VERSION ""

NS_ :

BS_:

BU_: PDC ADV APA GW LCDAM AVM

BO_ 3221225472 VECTOR__INDEPENDENT_SIG_MSG: 0 Vector__XXX
 SG_ FogLightSt_FR : 0|1@1+ (1,0) [0|1] "" Vector__XXX
 SG_ FogLightSt_FL : 0|1@1+ (1,0) [0|1] "" Vector__XXX
 SG_ PDC_SpeechControlFeedback : 0|3@1+ (1,0) [0|0] "" Vector__XXX
 SG_ MinObjectRange : 0|4@1+ (1,0) [0|0] "" Vector__XXX
 SG_ RadarSysSt_Side : 0|1@1+ (1,0) [0|0] "" Vector__XXX

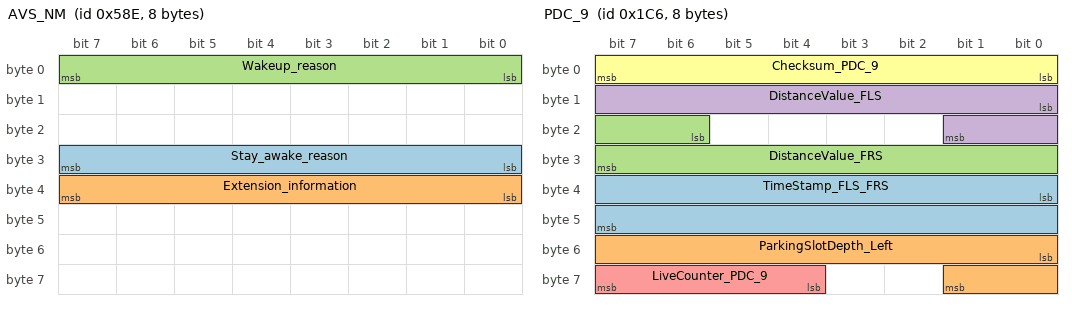
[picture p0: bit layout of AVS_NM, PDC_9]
BO_ 1422 AVS_NM: 8 AVM
 SG_ Stay_awake_reason : 24|8@1+ (1,0) [0|0] "" Vector__XXX
 SG_ Extension_information : 32|8@1+ (1,0) [0|0] "" Vector__XXX
 SG_ Wakeup_reason : 0|8@1+ (1,0) [0|0] "" Vector__XXX

BO_ 454 PDC_9: 8 APA
 SG_ TimeStamp_FLS_FRS : 32|16@1+ (1,0) [0|0] ""  AVM
 SG_ ParkingSlotDepth_Left : 48|10@1+ (1,0) [0|0] ""  AVM
 SG_ DistanceValue_FRS : 22|10@1+ (1,0) [0|0] ""  AVM
 SG_ DistanceValue_FLS : 8|10@1+ (1,0) [0|0] ""  AVM
 SG_ LiveCounter_PDC_9 : 60|4@1+ (1,0) [0|15] ""  AVM
 SG_ Checksum_PDC_9 : 0|8@1+ (1,0) [0|255] ""  AVM

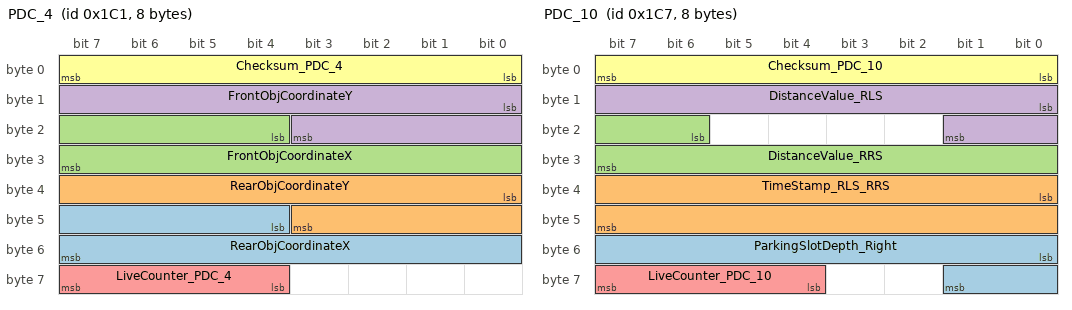
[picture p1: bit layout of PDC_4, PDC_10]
BO_ 449 PDC_4: 8 APA
 SG_ RearObjCoordinateX : 44|12@1+ (2,-4000) [-4000|4000] ""  AVM
 SG_ RearObjCoordinateY : 32|12@1+ (2,-4000) [-4000|4000] ""  AVM
 SG_ FrontObjCoordinateX : 20|12@1+ (2,-4000) [-4000|4000] ""  AVM
 SG_ FrontObjCoordinateY : 8|12@1+ (2,-4000) [-4000|4000] ""  AVM
 SG_ LiveCounter_PDC_4 : 60|4@1+ (1,0) [0|15] ""  AVM
 SG_ Checksum_PDC_4 : 0|8@1+ (1,0) [0|255] ""  AVM

BO_ 455 PDC_10: 8 APA
 SG_ ParkingSlotDepth_Right : 48|10@1+ (1,0) [0|0] ""  AVM
 SG_ TimeStamp_RLS_RRS : 32|16@1+ (1,0) [0|0] ""  AVM
 SG_ DistanceValue_RRS : 22|10@1+ (1,0) [0|0] ""  AVM
 SG_ DistanceValue_RLS : 8|10@1+ (1,0) [0|0] ""  AVM
 SG_ LiveCounter_PDC_10 : 60|4@1+ (1,0) [0|15] ""  AVM
 SG_ Checksum_PDC_10 : 0|8@1+ (1,0) [0|255] ""  AVM

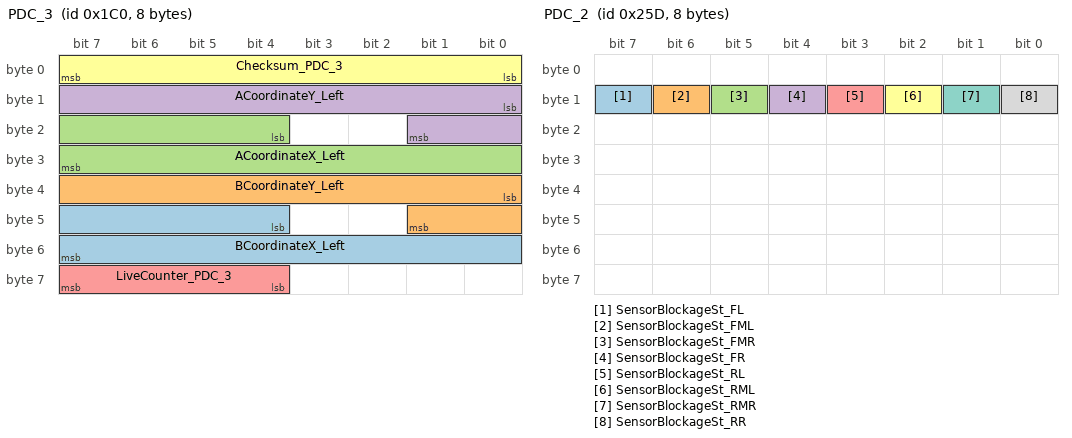
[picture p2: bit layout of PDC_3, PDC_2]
BO_ 448 PDC_3: 8 APA
 SG_ BCoordinateX_Left : 44|12@1+ (1,0) [0|0] ""  AVM
 SG_ BCoordinateY_Left : 32|10@1+ (1,0) [0|0] ""  AVM
 SG_ ACoordinateX_Left : 20|12@1+ (1,0) [0|0] ""  AVM
 SG_ ACoordinateY_Left : 8|10@1+ (1,0) [0|0] ""  AVM
 SG_ LiveCounter_PDC_3 : 60|4@1+ (1,0) [0|15] ""  AVM
 SG_ Checksum_PDC_3 : 0|8@1+ (1,0) [0|255] ""  AVM

BO_ 605 PDC_2: 8 PDC
 SG_ SensorBlockageSt_FL : 15|1@1+ (1,0) [0|0] ""  AVM
 SG_ SensorBlockageSt_FML : 14|1@1+ (1,0) [0|0] ""  AVM
 SG_ SensorBlockageSt_FMR : 13|1@1+ (1,0) [0|0] ""  AVM
 SG_ SensorBlockageSt_FR : 12|1@1+ (1,0) [0|0] ""  AVM
 SG_ SensorBlockageSt_RL : 11|1@1+ (1,0) [0|0] ""  AVM
 SG_ SensorBlockageSt_RML : 10|1@1+ (1,0) [0|0] ""  AVM
 SG_ SensorBlockageSt_RMR : 9|1@1+ (1,0) [0|0] ""  AVM
 SG_ SensorBlockageSt_RR : 8|1@1+ (1,0) [0|0] ""  AVM

BO_ 616 LCDA_1: 8 LCDAM
 SG_ WarningCmd_RCTA_Right : 20|2@1+ (1,0) [0|0] ""  AVM
 SG_ WarningCmd_RCTA_left : 16|2@1+ (1,0) [0|0] ""  AVM

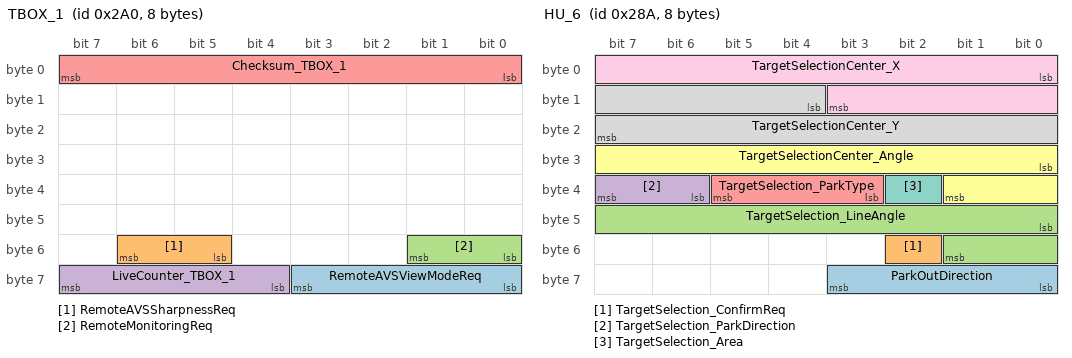
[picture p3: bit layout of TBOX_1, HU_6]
BO_ 672 TBOX_1: 8 GW
 SG_ RemoteAVSViewModeReq : 56|4@1+ (1,0) [0|0] ""  AVM
 SG_ RemoteAVSSharpnessReq : 53|2@1+ (1,0) [0|0] ""  AVM
 SG_ RemoteMonitoringReq : 48|2@1+ (1,0) [0|0] ""  AVM
 SG_ LiveCounter_TBOX_1 : 60|4@1+ (1,0) [0|15] ""  AVM
 SG_ Checksum_TBOX_1 : 0|8@1+ (1,0) [0|255] ""  AVM

BO_ 591 RRDCU_1: 8 GW
 SG_ DoorSt_RR : 2|1@1+ (1,0) [0|0] ""  AVM

BO_ 590 RLDCU_1: 8 GW
 SG_ DoorSt_RL : 2|1@1+ (1,0) [0|0] ""  AVM

BO_ 420 MCP_1: 8 GW
 SG_ MCP_AVSandFRadarSwitch : 25|1@1- (1,0) [0|0] ""  AVM

BO_ 650 HU_6: 8 GW
 SG_ ParkOutDirection : 56|4@1+ (1,0) [0|0] ""  AVM
 SG_ TargetSelection_ConfirmReq : 50|1@1+ (1,0) [0|0] ""  AVM
 SG_ TargetSelection_LineAngle : 40|10@1+ (1,0) [0|0] ""  AVM
 SG_ TargetSelection_ParkDirection : 38|2@1+ (1,0) [0|0] ""  AVM
 SG_ TargetSelection_ParkType : 35|3@1+ (1,0) [0|0] ""  AVM
 SG_ TargetSelectionCenter_Angle : 24|10@1+ (1,0) [0|360] ""  AVM
 SG_ TargetSelection_Area : 34|1@1+ (1,0) [0|0] ""  AVM
 SG_ TargetSelectionCenter_Y : 12|12@1+ (1,0) [0|719] ""  AVM
 SG_ TargetSelectionCenter_X : 0|12@1+ (1,0) [0|2607] ""  AVM

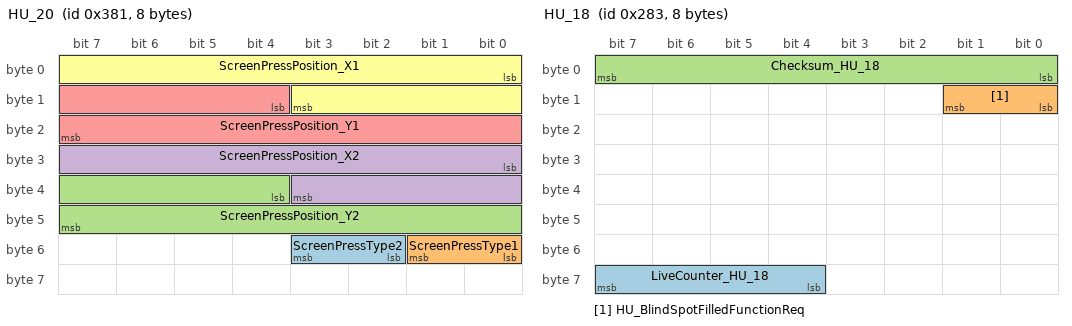
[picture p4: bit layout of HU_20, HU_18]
BO_ 897 HU_20: 8 GW
 SG_ ScreenPressType2 : 50|2@1+ (1,0) [0|0] ""  AVM
 SG_ ScreenPressType1 : 48|2@1+ (1,0) [0|0] ""  AVM
 SG_ ScreenPressPosition_Y2 : 36|12@1+ (1,0) [0|720] ""  AVM
 SG_ ScreenPressPosition_X2 : 24|12@1+ (1,0) [0|2607] ""  AVM
 SG_ ScreenPressPosition_Y1 : 12|12@1+ (1,0) [0|720] ""  AVM
 SG_ ScreenPressPosition_X1 : 0|12@1+ (1,0) [0|2607] ""  AVM

BO_ 643 HU_18: 8 GW
 SG_ LiveCounter_HU_18 : 60|4@1- (1,0) [0|0] ""  AVM
 SG_ HU_BlindSpotFilledFunctionReq : 8|2@1+ (1,0) [0|0] ""  AVM
 SG_ Checksum_HU_18 : 0|8@1+ (1,0) [0|0] ""  AVM

BO_ 657 HU_14: 8 GW
 SG_ DisplayTheme : 24|3@1+ (1,0) [0|0] ""  AVM

BO_ 688 GW_Config: 8 GW
 SG_ GW_OTAMode : 16|3@1+ (1,0) [0|0] ""  AVM
 SG_ GW_RemoteVehicleMode : 12|1@1+ (1,0) [0|0] ""  AVM

BO_ 534 DMS_2: 8 GW
 SG_ DMS_VehicleModeInfo : 8|4@1+ (1,0) [0|0] ""  AVM

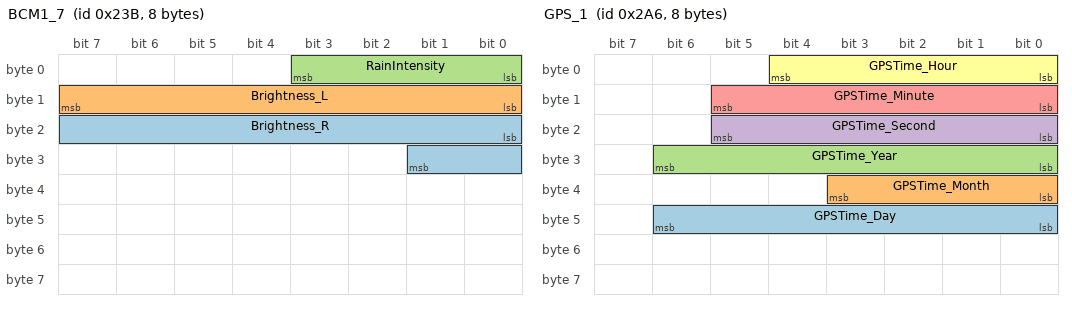
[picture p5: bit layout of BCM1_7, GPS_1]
BO_ 571 BCM1_7: 8 GW
 SG_ Brightness_R : 16|10@1+ (6,0) [0|0] ""  AVM
 SG_ Brightness_L : 8|8@1+ (400,0) [0|0] ""  AVM
 SG_ RainIntensity : 0|4@1+ (10,0) [0|0] ""  AVM

BO_ 564 BCM1_3: 8 GW
 SG_ EngineHoodSt : 12|1@1+ (1,0) [0|0] ""  AVM

BO_ 604 PDC_1: 8 PDC
 SG_ SwitchScreenRequest_PDC : 54|2@1+ (1,0) [0|0] ""  AVM
 SG_ PDCAutoOnFunctionInd : 53|1@1+ (1,0) [0|0] ""  AVM
 SG_ RadarSysSt_RearSide : 12|1@1- (1,0) [0|0] ""  AVM
 SG_ RadarSysSt_FrontSide : 11|1@1- (1,0) [0|0] ""  AVM
 SG_ SensorErrorSt_FL : 47|1@1+ (1,0) [0|0] ""  AVM
 SG_ ObjectRange_FL : 44|3@1+ (1,0) [0|0] ""  AVM
 SG_ SensorErrorSt_FML : 43|1@1+ (1,0) [0|0] ""  AVM
 SG_ ObjectRange_FML : 40|3@1+ (1,0) [0|0] ""  AVM
 SG_ SensorErrorSt_FMR : 39|1@1+ (1,0) [0|0] ""  AVM
 SG_ ObjectRange_FMR : 36|3@1+ (1,0) [0|0] ""  AVM
 SG_ SensorErrorSt_FR : 35|1@1+ (1,0) [0|0] ""  AVM
 SG_ ObjectRange_FR : 32|3@1+ (1,0) [0|0] ""  AVM
 SG_ SensorErrorSt_RL : 31|1@1+ (1,0) [0|0] ""  AVM
 SG_ ObjectRange_RL : 28|3@1+ (1,0) [0|7] ""  AVM
 SG_ SensorErrorSt_RML : 27|1@1+ (1,0) [0|0] ""  AVM
 SG_ ObjectRange_RML : 24|3@1+ (1,0) [0|0] ""  AVM
 SG_ SensorErrorSt_RMR : 23|1@1+ (1,0) [0|1] ""  AVM
 SG_ BuzeerCmd_PDC : 5|3@1+ (1,0) [0|0] ""  AVM
 SG_ ObjectRange_RMR : 20|3@1+ (1,0) [0|0] ""  AVM
 SG_ SensorErrorSt_RR : 19|1@1+ (1,0) [0|0] ""  AVM
 SG_ ObjectRange_RR : 16|3@1+ (1,0) [0|0] ""  AVM
 SG_ RadarSysSt_Rear : 3|1@1+ (1,0) [0|0] ""  AVM
 SG_ RadarSysSt_Front : 2|1@1+ (1,0) [0|0] ""  AVM
 SG_ ErrorSt_PDC : 1|1@1+ (1,0) [0|0] ""  AVM
 SG_ SysSt_PDC : 0|1@1+ (1,0) [0|0] ""  AVM

BO_ 546 ATC_2: 8 GW
 SG_ AmbientTemp : 24|8@1- (0.5,-40) [-40|86.5] ""  AVM

BO_ 678 GPS_1: 8 GW
 SG_ GPSTime_Day : 40|7@1+ (1,0) [0|30] ""  AVM
 SG_ GPSTime_Month : 32|4@1+ (1,0) [0|11] ""  AVM
 SG_ GPSTime_Year : 24|7@1+ (1,0) [0|125] ""  AVM
 SG_ GPSTime_Second : 16|6@1+ (1,0) [0|59] ""  AVM
 SG_ GPSTime_Minute : 8|6@1+ (1,0) [0|59] ""  AVM
 SG_ GPSTime_Hour : 0|5@1+ (1,0) [0|23] ""  AVM

BO_ 588 PDCU_1: 8 GW
 SG_ MirrorFoldSt_FR : 34|2@1+ (1,0) [0|0] ""  AVM
 SG_ DoorSt_FR : 2|1@1+ (1,0) [0|1] ""  AVM

BO_ 578 PLG_1: 8 GW
 SG_ LuggageDoorSt : 0|1@1+ (1,0) [0|0] ""  AVM

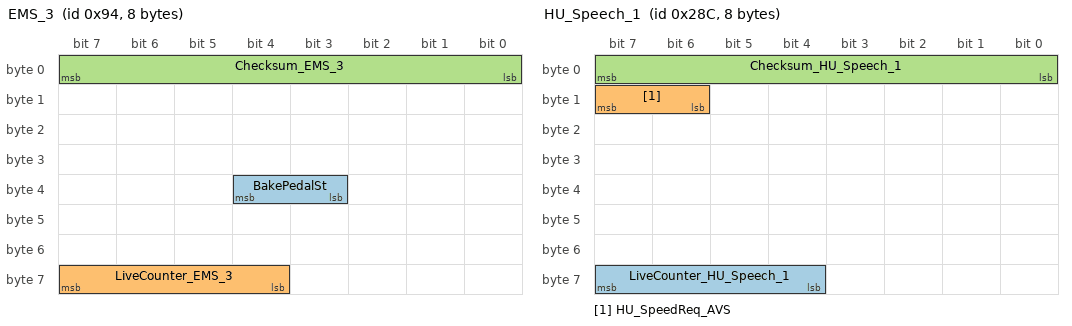
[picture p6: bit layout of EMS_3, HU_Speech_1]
BO_ 148 EMS_3: 8 GW
 SG_ BakePedalSt : 35|2@1+ (1,0) [0|0] ""  AVM
 SG_ LiveCounter_EMS_3 : 60|4@1+ (1,0) [0|15] ""  AVM
 SG_ Checksum_EMS_3 : 0|8@1+ (1,0) [0|255] ""  AVM

BO_ 652 HU_Speech_1: 8 GW
 SG_ LiveCounter_HU_Speech_1 : 60|4@1+ (1,0) [0|15] ""  PDC,AVM
 SG_ HU_SpeedReq_AVS : 14|2@1+ (1,0) [0|0] ""  PDC,AVM
 SG_ Checksum_HU_Speech_1 : 0|8@1+ (1,0) [0|255] ""  PDC,AVM

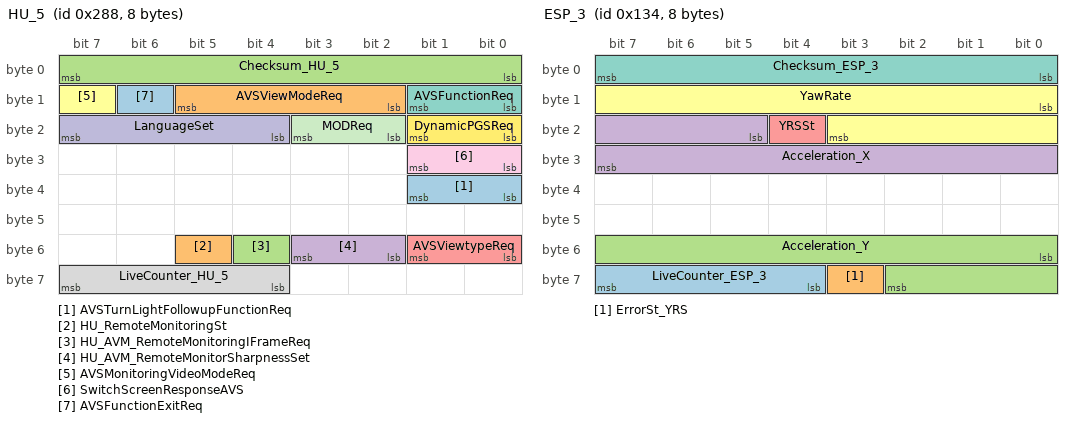
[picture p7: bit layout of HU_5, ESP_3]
BO_ 648 HU_5: 8 GW
 SG_ AVSTurnLightFollowupFunctionReq : 32|2@1+ (1,0) [0|0] ""  AVM
 SG_ HU_RemoteMonitoringSt : 53|1@1+ (1,0) [0|0] ""  AVM
 SG_ HU_AVM_RemoteMonitoringIFrameReq : 52|1@1+ (1,0) [0|0] ""  AVM
 SG_ HU_AVM_RemoteMonitorSharpnessSet : 50|2@1+ (1,0) [0|0] ""  AVM
 SG_ AVSViewtypeReq : 48|2@1+ (1,0) [0|0] ""  AVM
 SG_ AVSMonitoringVideoModeReq : 15|1@1+ (1,0) [0|0] ""  AVM
 SG_ AVSFunctionReq : 8|2@1+ (1,0) [0|0] ""  AVM
 SG_ LiveCounter_HU_5 : 60|4@1+ (1,0) [0|15] ""  AVM
 SG_ SwitchScreenResponseAVS : 24|2@1+ (1,0) [0|0] ""  AVM
 SG_ LanguageSet : 20|4@1+ (1,0) [0|0] ""  AVM
 SG_ MODReq : 18|2@1+ (1,0) [0|0] ""  AVM
 SG_ DynamicPGSReq : 16|2@1+ (1,0) [0|0] ""  AVM
 SG_ AVSFunctionExitReq : 14|1@1+ (1,0) [0|0] ""  AVM
 SG_ AVSViewModeReq : 10|4@1+ (1,0) [0|0] ""  AVM
 SG_ Checksum_HU_5 : 0|8@1+ (1,0) [0|255] ""  AVM

BO_ 308 ESP_3: 8 GW
 SG_ LiveCounter_ESP_3 : 60|4@1+ (1,0) [0|0] ""  AVM
 SG_ ErrorSt_YRS : 59|1@1+ (1,0) [0|0] ""  AVM
 SG_ Acceleration_Y : 48|11@1- (0.027127,-21.593) [-21.593|21.593184] ""  AVM
 SG_ Acceleration_X : 21|11@1+ (0.027127,-21.593) [-21.593|21.593184] ""  AVM
 SG_ YRSSt : 20|1@1+ (1,0) [0|15] ""  AVM
 SG_ YawRate : 8|12@1- (0.05,-100) [-100|100] ""  AVM
 SG_ Checksum_ESP_3 : 0|8@1+ (1,0) [0|255] ""  AVM

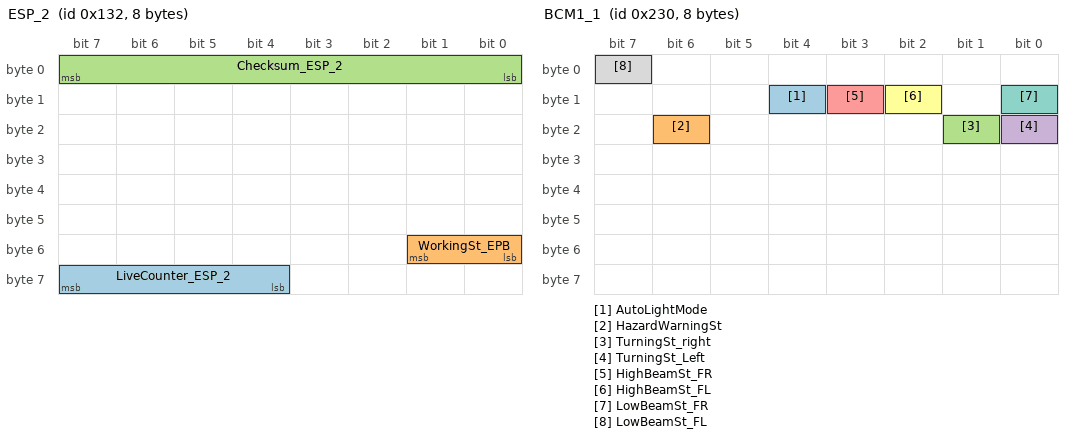
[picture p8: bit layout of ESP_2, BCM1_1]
BO_ 306 ESP_2: 8 GW
 SG_ LiveCounter_ESP_2 : 60|4@1+ (1,0) [0|15] ""  AVM
 SG_ WorkingSt_EPB : 48|2@1+ (1,0) [0|0] ""  AVM
 SG_ Checksum_ESP_2 : 0|8@1+ (1,0) [0|255] ""  AVM

BO_ 586 DDCU_1: 8 GW
 SG_ DoorSt_FL : 2|1@1+ (1,0) [0|0] ""  AVM
 SG_ MirrorFoldSt_FL : 34|2@1+ (1,0) [0|0] ""  AVM

BO_ 560 BCM1_1: 8 GW
 SG_ AutoLightMode : 12|1@1+ (1,0) [0|0] ""  AVM
 SG_ HazardWarningSt : 22|1@1+ (1,0) [0|15] ""  AVM
 SG_ TurningSt_right : 17|1@1+ (1,0) [0|3] ""  AVM
 SG_ TurningSt_Left : 16|1@1+ (1,0) [0|1] ""  AVM
 SG_ HighBeamSt_FR : 11|1@1+ (1,0) [0|1] ""  AVM
 SG_ HighBeamSt_FL : 10|1@1+ (1,0) [0|1] ""  AVM
 SG_ LowBeamSt_FR : 8|1@1+ (1,0) [0|1] ""  AVM
 SG_ LowBeamSt_FL : 7|1@1+ (1,0) [0|1] ""  AVM

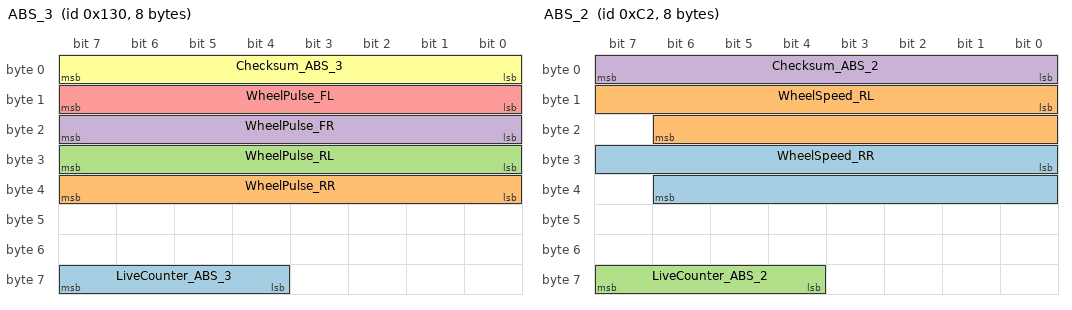
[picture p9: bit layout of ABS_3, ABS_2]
BO_ 304 ABS_3: 8 GW
 SG_ LiveCounter_ABS_3 : 60|4@1+ (1,0) [0|15] ""  AVM
 SG_ WheelPulse_RR : 32|8@1+ (1,0) [0|253] ""  AVM
 SG_ WheelPulse_RL : 24|8@1+ (1,0) [0|253] ""  AVM
 SG_ WheelPulse_FR : 16|8@1+ (1,0) [0|253] ""  AVM
 SG_ WheelPulse_FL : 8|8@1+ (1,0) [0|253] ""  AVM
 SG_ Checksum_ABS_3 : 0|8@1+ (1,0) [0|255] ""  AVM

BO_ 194 ABS_2: 8 GW
 SG_ WheelSpeed_RR : 24|15@1+ (0.01,0) [0|32765] ""  AVM
 SG_ WheelSpeed_RL : 8|15@1+ (0.01,0) [0|32765] ""  AVM
 SG_ LiveCounter_ABS_2 : 60|4@1+ (1,0) [0|15] ""  AVM
 SG_ Checksum_ABS_2 : 0|8@1+ (1,0) [0|255] ""  AVM

BO_ 2015 Diag_Fun_Req: 8 GW
 SG_ Diag_Fun_Req : 0|64@1+ (1,0) [0|0] ""  AVM,GW

BO_ 1838 AVS_Phy_Resp: 8 AVM
 SG_ AVS_Phy_Resp : 0|64@1+ (1,0) [0|0] ""  GW

BO_ 1830 AVS_Phy_Req: 8 GW
 SG_ AVS_Phy_Req : 0|64@1+ (1,0) [0|0] ""  AVM

BO_ 656 IC_1: 8 GW
 SG_ HandParkingBrakeSt : 49|2@1+ (1,0) [0|0] ""  AVM,PDC
 SG_ OdometerValue : 24|25@1+ (0.1,0) [0|33554430] ""  AVM

BO_ 562 BCM1_2: 8 GW
 SG_ PowerMode : 4|4@1- (1,0) [0|0] ""  AVM

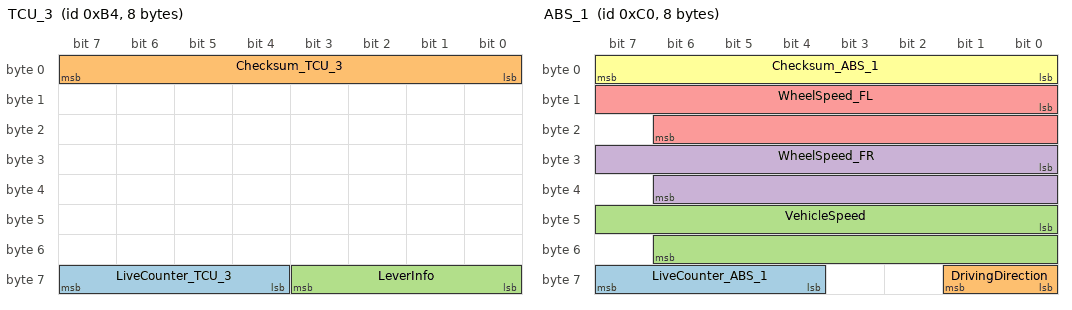
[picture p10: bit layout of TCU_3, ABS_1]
BO_ 180 TCU_3: 8 GW
 SG_ LiveCounter_TCU_3 : 60|4@1+ (1,0) [0|15] ""  PDC
 SG_ Checksum_TCU_3 : 0|8@1+ (1,0) [0|255] ""  PDC
 SG_ LeverInfo : 56|4@1+ (1,0) [0|15] ""  AVM

BO_ 192 ABS_1: 8 GW
 SG_ LiveCounter_ABS_1 : 60|4@1+ (1,0) [0|15] ""  AVM
 SG_ DrivingDirection : 56|2@1+ (1,0) [0|3] ""  AVM
 SG_ VehicleSpeed : 40|15@1+ (0.01,0) [0|32765] ""  AVM
 SG_ WheelSpeed_FR : 24|15@1+ (0.01,0) [0|32765] ""  AVM
 SG_ WheelSpeed_FL : 8|15@1+ (0.01,0) [0|32765] ""  AVM
 SG_ Checksum_ABS_1 : 0|8@1+ (1,0) [0|255] ""  AVM

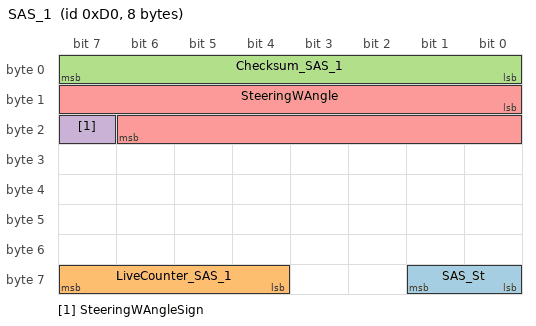
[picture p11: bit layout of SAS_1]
BO_ 208 SAS_1: 8 GW
 SG_ SAS_St : 56|2@1+ (1,0) [0|0] ""  AVM
 SG_ LiveCounter_SAS_1 : 60|4@1+ (1,0) [0|15] ""  AVM
 SG_ Checksum_SAS_1 : 0|8@1+ (1,0) [0|255] ""  AVM
 SG_ SteeringWAngleSign : 23|1@1+ (1,0) [0|1] ""  AVM
 SG_ SteeringWAngle : 8|15@1+ (0.04375,0) [0|32766] ""  AVM

BO_ 600 AVS_1: 8 AVM
 SG_ AVSTurnLightFollowupFunctionSt : 20|1@1+ (1,0) [0|0] ""  GW
 SG_ AVS_RemoteViewModeFeedback : 59|5@1+ (1,0) [0|0] ""  GW
 SG_ RemoteMonitoringModeSt_AVS : 56|1@1+ (1,0) [0|0] ""  GW
 SG_ RemoteMonitoringSt_AVS : 55|1@1+ (1,0) [0|0] ""  GW
 SG_ RemoteMonitoringSharpnessSt_AVS : 54|1@1+ (1,0) [0|0] ""  GW
 SG_ AVS_RemoteSharpnessFeedback : 51|3@1+ (1,0) [0|0] ""  GW
 SG_ AVS_RemoteMonitoringFeedback : 48|3@1+ (1,0) [0|0] ""  GW
 SG_ AVS_PDWarning_Rear : 47|1@1+ (1,0) [0|0] ""  GW
 SG_ AVS_PDWarning_Front : 46|1@1+ (1,0) [0|0] ""  GW
 SG_ AVS_CalibrationSt : 44|2@1+ (1,0) [0|0] ""  ADV
 SG_ AVS_AbnormalTip : 41|3@1+ (1,0) [0|0] ""  GW
 SG_ AVSCameraBlockageSt_Right : 40|1@1+ (1,0) [0|0] ""  GW
 SG_ AVSCameraBlockageSt_Left : 39|1@1+ (1,0) [0|0] ""  GW
 SG_ AVSCameraBlockageSt_Rear : 38|1@1+ (1,0) [0|0] ""  GW
 SG_ AVSCameraBlockageSt_Front : 37|1@1+ (1,0) [0|0] ""  GW
 SG_ FoundSlotBuzzerTip : 27|1@1+ (1,0) [0|0] ""  GW
 SG_ BlindSpotFilledFunctionInd : 26|1@1+ (1,0) [0|0] ""  GW,ADV
 SG_ MODWarning_Rear : 19|1@1+ (1,0) [0|0] ""  ADV,GW
 SG_ MODWarning_Front : 18|1@1+ (1,0) [0|0] ""  ADV,GW
 SG_ MODSt_AVS : 17|1@1+ (1,0) [0|0] ""  GW
 SG_ AVSViewtype : 6|2@1+ (1,0) [0|0] ""  GW
 SG_ AVS_SpeechControlFeedback : 32|5@1+ (1,0) [0|0] "" Vector__XXX
 SG_ SwitchScreenRequest_AVS : 24|2@1+ (1,0) [0|0] ""  GW
 SG_ DybanicPGSSt_AVS : 16|1@1+ (1,0) [0|0] ""  GW
 SG_ AVSCameraErrorSt_Right : 11|1@1+ (1,0) [0|0] ""  GW
 SG_ AVSCameraErrorSt_Rear : 9|1@1+ (1,0) [0|0] ""  GW
 SG_ AVSCameraErrorSt_Left : 10|1@1+ (1,0) [0|0] ""  GW
 SG_ LanguageTypeSt_AVS : 12|4@1+ (1,0) [0|7] ""  GW
 SG_ AVSCameraErrorSt_Front : 8|1@1+ (1,0) [0|0] ""  GW
 SG_ AVSSt : 0|1@1+ (1,0) [0|0] ""  PDC,GW
 SG_ AVSViewMode : 2|4@1+ (1,0) [0|7] ""  GW
 SG_ AVSErrorSt : 1|1@1+ (1,0) [0|1] ""  ADV,GW

BO_TX_BU_ 605 : APA,PDC;
BO_TX_BU_ 604 : APA,PDC;

CM_ "

";
CM_ BO_ 3221225472 "This is a message for not used signals, created by Vector CANdb++ DBC OLE DB Provider.";
BA_DEF_ BO_  "GenSigTimeoutTime_DUT" INT 0 100000;
BA_DEF_ BU_  "NmStationAddress" HEX 0 255;
BA_DEF_ SG_  "GenSigInactiveValue" INT 0 100000;
BA_DEF_ SG_  "GenSigSendType" ENUM  "Cyclic","OnWrite","OnWriteWithRepetition","OnChange","OnChangeWithRepetition","IfActive","IfActiveWithRepetition","NoSigSendType","OnChangeAndIfActive","OnChangeAndIfActiveWithRepetition";
BA_DEF_ SG_  "GenSigStartValue" INT 0 65535;
BA_DEF_ BO_  "GenMsgCycleTime" INT 0 65535;
BA_DEF_ BO_  "GenMsgSendType" ENUM  "Cyclic ","NotUsed ","NotUsed ","NotUsed ","NotUsed ","NotUsed ","NotUsed ","IfActive ","NoMsgSendType";
BA_DEF_ BO_  "DiagRequest" ENUM  "No","Yes";
BA_DEF_ BO_  "DiagResponse" ENUM  "No","Yes";
BA_DEF_ BO_  "DiagState" ENUM  "No","Yes";
BA_DEF_ BO_  "GenMsgILSupport" ENUM  "No","Yes";
BA_DEF_ BU_  "ILUsed" ENUM  "No","Yes";
BA_DEF_ BU_  "NmAsrNode" ENUM  "No","Yes";
BA_DEF_  "Baudrate" INT 0 0;
BA_DEF_  "NmType" STRING ;
BA_DEF_  "Manufacturer" STRING ;
BA_DEF_  "ILTxTimeout" INT 0 65535;
BA_DEF_  "DBName" STRING ;
BA_DEF_  "BusType" STRING ;
BA_DEF_ BO_  "NmAsrMessage" ENUM  "No","Yes";
BA_DEF_ BU_  "NmAsrCanMsgReducedTime" INT 0 0;
BA_DEF_  "NmAsrRepeatMessageTime" INT 0 0;
BA_DEF_  "NmAsrWaitBusSleepTime" INT 0 0;
BA_DEF_  "NmAsrTimeoutTime" INT 0 0;
BA_DEF_  "NmAsrCanMsgCycleTime" INT 0 0;
BA_DEF_  "NmAsrMessageCount" INT 0 256;
BA_DEF_ BU_  "NmAsrNodeIdentifier" HEX 0 255;
BA_DEF_  "NmAsrBaseAddress" HEX 0 0;
BA_DEF_ SG_  "GenSigTimeoutTime" INT 0 65535;
BA_DEF_DEF_  "GenSigTimeoutTime_DUT" 0;
BA_DEF_DEF_  "NmStationAddress" 0;
BA_DEF_DEF_  "GenSigInactiveValue" 0;
BA_DEF_DEF_  "GenSigSendType" "NoSigSendType";
BA_DEF_DEF_  "GenSigStartValue" 0;
BA_DEF_DEF_  "GenMsgCycleTime" 0;
BA_DEF_DEF_  "GenMsgSendType" "NoMsgSendType";
BA_DEF_DEF_  "DiagRequest" "No";
BA_DEF_DEF_  "DiagResponse" "No";
BA_DEF_DEF_  "DiagState" "No";
BA_DEF_DEF_  "GenMsgILSupport" "Yes";
BA_DEF_DEF_  "ILUsed" "Yes";
BA_DEF_DEF_  "NmAsrNode" "No";
BA_DEF_DEF_  "Baudrate" 500000;
BA_DEF_DEF_  "NmType" "NmPwrTrainChery";
BA_DEF_DEF_  "Manufacturer" "Chery";
BA_DEF_DEF_  "ILTxTimeout" 40;
BA_DEF_DEF_  "DBName" "";
BA_DEF_DEF_  "BusType" "CAN";
BA_DEF_DEF_  "NmAsrMessage" "No";
BA_DEF_DEF_  "NmAsrCanMsgReducedTime" 0;
BA_DEF_DEF_  "NmAsrRepeatMessageTime" 3200;
BA_DEF_DEF_  "NmAsrWaitBusSleepTime" 1500;
BA_DEF_DEF_  "NmAsrTimeoutTime" 2000;
BA_DEF_DEF_  "NmAsrCanMsgCycleTime" 640;
BA_DEF_DEF_  "NmAsrMessageCount" 64;
BA_DEF_DEF_  "NmAsrNodeIdentifier" 0;
BA_DEF_DEF_  "NmAsrBaseAddress" 0;
BA_DEF_DEF_  "GenSigTimeoutTime" 0;
BA_ "NmAsrTimeoutTime" 1000;
BA_ "NmAsrMessageCount" 128;
BA_ "NmAsrCanMsgCycleTime" 100;
BA_ "NmAsrWaitBusSleepTime" 5000;
BA_ "NmAsrRepeatMessageTime" 500;
BA_ "Manufacturer" "Vector";
BA_ "NmType" "NmAsr";
BA_ "ILTxTimeout" 0;
BA_ "NmAsrBaseAddress" 1408;
BA_ "DBName" "AB02_FAW_C095";
BA_ "NmStationAddress" BU_ AVM 14;
BA_ "NmAsrNode" BU_ AVM 1;
BA_ "NmAsrCanMsgReducedTime" BU_ AVM 575;
BA_ "NmAsrNodeIdentifier" BU_ AVM 14;
BA_ "NmAsrMessage" BO_ 1422 1;
BA_ "GenMsgILSupport" BO_ 1422 0;
BA_ "GenMsgSendType" BO_ 1422 0;
BA_ "GenMsgCycleTime" BO_ 1422 100;
BA_ "GenMsgSendType" BO_ 454 0;
BA_ "GenMsgCycleTime" BO_ 454 50;
BA_ "GenMsgSendType" BO_ 449 0;
BA_ "GenMsgCycleTime" BO_ 449 50;
BA_ "GenMsgSendType" BO_ 455 0;
BA_ "GenMsgCycleTime" BO_ 455 50;
BA_ "GenMsgSendType" BO_ 448 0;
BA_ "GenMsgCycleTime" BO_ 448 50;
BA_ "GenMsgSendType" BO_ 605 0;
BA_ "GenMsgCycleTime" BO_ 605 100;
BA_ "GenMsgSendType" BO_ 616 0;
BA_ "GenMsgCycleTime" BO_ 616 100;
BA_ "GenMsgSendType" BO_ 672 0;
BA_ "GenMsgCycleTime" BO_ 672 100;
BA_ "GenMsgSendType" BO_ 591 0;
BA_ "GenMsgCycleTime" BO_ 591 100;
BA_ "GenMsgSendType" BO_ 590 0;
BA_ "GenMsgCycleTime" BO_ 590 100;
BA_ "GenMsgSendType" BO_ 420 0;
BA_ "GenMsgCycleTime" BO_ 420 50;
BA_ "GenMsgSendType" BO_ 650 0;
BA_ "GenMsgCycleTime" BO_ 650 100;
BA_ "GenMsgSendType" BO_ 897 0;
BA_ "GenMsgCycleTime" BO_ 897 100;
BA_ "GenMsgSendType" BO_ 643 0;
BA_ "GenMsgCycleTime" BO_ 643 100;
BA_ "GenMsgSendType" BO_ 657 0;
BA_ "GenMsgCycleTime" BO_ 657 100;
BA_ "GenMsgSendType" BO_ 688 0;
BA_ "GenMsgCycleTime" BO_ 688 100;
BA_ "GenMsgSendType" BO_ 534 0;
BA_ "GenMsgCycleTime" BO_ 534 100;
BA_ "GenSigTimeoutTime_DUT" BO_ 534 500;
BA_ "GenMsgSendType" BO_ 571 0;
BA_ "GenMsgCycleTime" BO_ 571 100;
BA_ "GenSigTimeoutTime_DUT" BO_ 571 500;
BA_ "GenMsgSendType" BO_ 564 0;
BA_ "GenMsgCycleTime" BO_ 564 100;
BA_ "GenSigTimeoutTime_DUT" BO_ 564 500;
BA_ "GenMsgCycleTime" BO_ 604 100;
BA_ "GenMsgSendType" BO_ 604 0;
BA_ "GenMsgCycleTime" BO_ 546 100;
BA_ "GenMsgSendType" BO_ 546 0;
BA_ "GenMsgSendType" BO_ 678 0;
BA_ "GenMsgCycleTime" BO_ 678 100;
BA_ "GenMsgSendType" BO_ 588 0;
BA_ "GenMsgCycleTime" BO_ 588 100;
BA_ "GenMsgSendType" BO_ 578 0;
BA_ "GenMsgCycleTime" BO_ 578 100;
BA_ "GenMsgSendType" BO_ 148 0;
BA_ "GenMsgCycleTime" BO_ 148 10;
BA_ "GenMsgSendType" BO_ 652 0;
BA_ "GenMsgCycleTime" BO_ 652 100;
BA_ "GenMsgCycleTime" BO_ 648 100;
BA_ "GenMsgSendType" BO_ 648 0;
BA_ "GenMsgSendType" BO_ 308 0;
BA_ "GenMsgCycleTime" BO_ 308 20;
BA_ "GenMsgCycleTime" BO_ 306 20;
BA_ "GenMsgSendType" BO_ 306 0;
BA_ "GenMsgCycleTime" BO_ 586 100;
BA_ "GenMsgSendType" BO_ 586 0;
BA_ "GenMsgCycleTime" BO_ 560 100;
BA_ "GenMsgSendType" BO_ 560 0;
BA_ "GenMsgCycleTime" BO_ 304 20;
BA_ "GenMsgSendType" BO_ 304 0;
BA_ "GenMsgSendType" BO_ 194 0;
BA_ "GenMsgCycleTime" BO_ 194 10;
BA_ "DiagState" BO_ 2015 1;
BA_ "DiagResponse" BO_ 1838 1;
BA_ "DiagRequest" BO_ 1830 1;
BA_ "GenMsgSendType" BO_ 1830 0;
BA_ "GenMsgSendType" BO_ 656 0;
BA_ "GenMsgCycleTime" BO_ 656 100;
BA_ "GenSigTimeoutTime_DUT" BO_ 562 500;
BA_ "GenMsgCycleTime" BO_ 562 100;
BA_ "GenMsgSendType" BO_ 562 0;
BA_ "GenMsgCycleTime" BO_ 180 10;
BA_ "GenMsgSendType" BO_ 180 0;
BA_ "GenMsgCycleTime" BO_ 192 10;
BA_ "GenMsgSendType" BO_ 192 0;
BA_ "GenMsgCycleTime" BO_ 208 10;
BA_ "GenMsgSendType" BO_ 208 0;
BA_ "GenMsgCycleTime" BO_ 600 100;
BA_ "GenMsgSendType" BO_ 600 0;
BA_ "GenSigSendType" SG_ 3221225472 FogLightSt_FR 0;
BA_ "GenSigSendType" SG_ 3221225472 FogLightSt_FL 0;
BA_ "GenSigSendType" SG_ 3221225472 PDC_SpeechControlFeedback 1;
BA_ "GenSigSendType" SG_ 3221225472 MinObjectRange 1;
BA_ "GenSigSendType" SG_ 3221225472 RadarSysSt_Side 1;
BA_ "GenSigSendType" SG_ 1422 Stay_awake_reason 0;
BA_ "GenSigSendType" SG_ 1422 Extension_information 0;
BA_ "GenSigSendType" SG_ 1422 Wakeup_reason 0;
BA_ "GenSigSendType" SG_ 454 TimeStamp_FLS_FRS 0;
BA_ "GenSigSendType" SG_ 454 ParkingSlotDepth_Left 0;
BA_ "GenSigSendType" SG_ 454 DistanceValue_FRS 0;
BA_ "GenSigSendType" SG_ 454 DistanceValue_FLS 0;
BA_ "GenSigSendType" SG_ 454 LiveCounter_PDC_9 0;
BA_ "GenSigSendType" SG_ 454 Checksum_PDC_9 0;
BA_ "GenSigSendType" SG_ 449 RearObjCoordinateX 0;
BA_ "GenSigStartValue" SG_ 449 RearObjCoordinateX 2000;
BA_ "GenSigSendType" SG_ 449 RearObjCoordinateY 0;
BA_ "GenSigStartValue" SG_ 449 RearObjCoordinateY 2000;
BA_ "GenSigStartValue" SG_ 449 FrontObjCoordinateX 2000;
BA_ "GenSigSendType" SG_ 449 FrontObjCoordinateX 0;
BA_ "GenSigStartValue" SG_ 449 FrontObjCoordinateY 2000;
BA_ "GenSigSendType" SG_ 449 FrontObjCoordinateY 0;
BA_ "GenSigSendType" SG_ 449 LiveCounter_PDC_4 0;
BA_ "GenSigSendType" SG_ 449 Checksum_PDC_4 0;
BA_ "GenSigSendType" SG_ 455 ParkingSlotDepth_Right 0;
BA_ "GenSigSendType" SG_ 455 TimeStamp_RLS_RRS 0;
BA_ "GenSigSendType" SG_ 455 DistanceValue_RRS 0;
BA_ "GenSigSendType" SG_ 455 DistanceValue_RLS 0;
BA_ "GenSigSendType" SG_ 455 LiveCounter_PDC_10 0;
BA_ "GenSigSendType" SG_ 455 Checksum_PDC_10 0;
BA_ "GenSigSendType" SG_ 448 BCoordinateX_Left 0;
BA_ "GenSigSendType" SG_ 448 BCoordinateY_Left 0;
BA_ "GenSigSendType" SG_ 448 ACoordinateX_Left 0;
BA_ "GenSigSendType" SG_ 448 ACoordinateY_Left 0;
BA_ "GenSigSendType" SG_ 448 LiveCounter_PDC_3 0;
BA_ "GenSigSendType" SG_ 448 Checksum_PDC_3 0;
BA_ "GenSigSendType" SG_ 605 SensorBlockageSt_FL 0;
BA_ "GenSigSendType" SG_ 605 SensorBlockageSt_FML 0;
BA_ "GenSigSendType" SG_ 605 SensorBlockageSt_FMR 0;
BA_ "GenSigSendType" SG_ 605 SensorBlockageSt_FR 0;
BA_ "GenSigSendType" SG_ 605 SensorBlockageSt_RL 0;
BA_ "GenSigSendType" SG_ 605 SensorBlockageSt_RML 0;
BA_ "GenSigSendType" SG_ 605 SensorBlockageSt_RMR 0;
BA_ "GenSigSendType" SG_ 605 SensorBlockageSt_RR 0;
BA_ "GenSigSendType" SG_ 616 WarningCmd_RCTA_Right 0;
BA_ "GenSigSendType" SG_ 616 WarningCmd_RCTA_left 0;
BA_ "GenSigSendType" SG_ 672 RemoteAVSViewModeReq 0;
BA_ "GenSigSendType" SG_ 672 RemoteAVSSharpnessReq 0;
BA_ "GenSigSendType" SG_ 672 RemoteMonitoringReq 0;
BA_ "GenSigSendType" SG_ 672 LiveCounter_TBOX_1 0;
BA_ "GenSigSendType" SG_ 672 Checksum_TBOX_1 0;
BA_ "GenSigSendType" SG_ 591 DoorSt_RR 0;
BA_ "GenSigSendType" SG_ 590 DoorSt_RL 0;
BA_ "GenSigSendType" SG_ 420 MCP_AVSandFRadarSwitch 0;
BA_ "GenSigSendType" SG_ 897 ScreenPressType2 0;
BA_ "GenSigSendType" SG_ 897 ScreenPressType1 0;
BA_ "GenSigSendType" SG_ 897 ScreenPressPosition_Y2 1;
BA_ "GenSigSendType" SG_ 897 ScreenPressPosition_X2 1;
BA_ "GenSigSendType" SG_ 897 ScreenPressPosition_Y1 1;
BA_ "GenSigSendType" SG_ 897 ScreenPressPosition_X1 1;
BA_ "GenSigSendType" SG_ 643 LiveCounter_HU_18 0;
BA_ "GenSigSendType" SG_ 643 HU_BlindSpotFilledFunctionReq 0;
BA_ "GenSigSendType" SG_ 643 Checksum_HU_18 0;
BA_ "GenSigSendType" SG_ 657 DisplayTheme 0;
BA_ "GenSigSendType" SG_ 688 GW_OTAMode 0;
BA_ "GenSigSendType" SG_ 688 GW_RemoteVehicleMode 0;
BA_ "GenSigSendType" SG_ 534 DMS_VehicleModeInfo 0;
BA_ "GenSigSendType" SG_ 571 Brightness_R 0;
BA_ "GenSigSendType" SG_ 571 Brightness_L 0;
BA_ "GenSigSendType" SG_ 571 RainIntensity 0;
BA_ "GenSigSendType" SG_ 564 EngineHoodSt 0;
BA_ "GenSigSendType" SG_ 604 SwitchScreenRequest_PDC 0;
BA_ "GenSigSendType" SG_ 604 PDCAutoOnFunctionInd 0;
BA_ "GenSigSendType" SG_ 604 RadarSysSt_RearSide 1;
BA_ "GenSigSendType" SG_ 604 RadarSysSt_FrontSide 1;
BA_ "GenSigSendType" SG_ 604 SensorErrorSt_FL 1;
BA_ "GenSigSendType" SG_ 604 ObjectRange_FL 1;
BA_ "GenSigSendType" SG_ 604 SensorErrorSt_FML 1;
BA_ "GenSigSendType" SG_ 604 ObjectRange_FML 1;
BA_ "GenSigSendType" SG_ 604 SensorErrorSt_FMR 1;
BA_ "GenSigSendType" SG_ 604 ObjectRange_FMR 1;
BA_ "GenSigSendType" SG_ 604 SensorErrorSt_FR 1;
BA_ "GenSigSendType" SG_ 604 ObjectRange_FR 1;
BA_ "GenSigSendType" SG_ 604 SensorErrorSt_RL 1;
BA_ "GenSigSendType" SG_ 604 ObjectRange_RL 1;
BA_ "GenSigSendType" SG_ 604 SensorErrorSt_RML 1;
BA_ "GenSigSendType" SG_ 604 ObjectRange_RML 1;
BA_ "GenSigSendType" SG_ 604 SensorErrorSt_RMR 1;
BA_ "GenSigSendType" SG_ 604 BuzeerCmd_PDC 1;
BA_ "GenSigSendType" SG_ 604 ObjectRange_RMR 1;
BA_ "GenSigSendType" SG_ 604 SensorErrorSt_RR 1;
BA_ "GenSigSendType" SG_ 604 ObjectRange_RR 1;
BA_ "GenSigSendType" SG_ 604 RadarSysSt_Rear 1;
BA_ "GenSigSendType" SG_ 604 RadarSysSt_Front 1;
BA_ "GenSigSendType" SG_ 604 ErrorSt_PDC 1;
BA_ "GenSigSendType" SG_ 604 SysSt_PDC 1;
BA_ "GenSigSendType" SG_ 546 AmbientTemp 0;
BA_ "GenSigStartValue" SG_ 546 AmbientTemp 80;
BA_ "GenSigSendType" SG_ 678 GPSTime_Day 0;
BA_ "GenSigSendType" SG_ 678 GPSTime_Month 0;
BA_ "GenSigSendType" SG_ 678 GPSTime_Year 0;
BA_ "GenSigSendType" SG_ 678 GPSTime_Second 0;
BA_ "GenSigSendType" SG_ 678 GPSTime_Minute 0;
BA_ "GenSigSendType" SG_ 678 GPSTime_Hour 0;
BA_ "GenSigSendType" SG_ 588 MirrorFoldSt_FR 0;
BA_ "GenSigSendType" SG_ 588 DoorSt_FR 0;
BA_ "GenSigSendType" SG_ 578 LuggageDoorSt 1;
BA_ "GenSigSendType" SG_ 148 BakePedalSt 0;
BA_ "GenSigSendType" SG_ 148 LiveCounter_EMS_3 0;
BA_ "GenSigSendType" SG_ 148 Checksum_EMS_3 0;
BA_ "GenSigSendType" SG_ 652 LiveCounter_HU_Speech_1 1;
BA_ "GenSigSendType" SG_ 652 HU_SpeedReq_AVS 1;
BA_ "GenSigSendType" SG_ 652 Checksum_HU_Speech_1 1;
BA_ "GenSigSendType" SG_ 648 AVSTurnLightFollowupFunctionReq 0;
BA_ "GenSigSendType" SG_ 648 HU_RemoteMonitoringSt 0;
BA_ "GenSigSendType" SG_ 648 HU_AVM_RemoteMonitoringIFrameReq 0;
BA_ "GenSigSendType" SG_ 648 HU_AVM_RemoteMonitorSharpnessSet 0;
BA_ "GenSigSendType" SG_ 648 AVSViewtypeReq 1;
BA_ "GenSigSendType" SG_ 648 AVSMonitoringVideoModeReq 0;
BA_ "GenSigSendType" SG_ 648 AVSFunctionReq 0;
BA_ "GenSigSendType" SG_ 648 LiveCounter_HU_5 1;
BA_ "GenSigSendType" SG_ 648 SwitchScreenResponseAVS 1;
BA_ "GenSigSendType" SG_ 648 LanguageSet 1;
BA_ "GenSigSendType" SG_ 648 MODReq 1;
BA_ "GenSigSendType" SG_ 648 DynamicPGSReq 1;
BA_ "GenSigSendType" SG_ 648 AVSFunctionExitReq 1;
BA_ "GenSigSendType" SG_ 648 AVSViewModeReq 1;
BA_ "GenSigSendType" SG_ 648 Checksum_HU_5 1;
BA_ "GenSigSendType" SG_ 308 LiveCounter_ESP_3 0;
BA_ "GenSigSendType" SG_ 308 ErrorSt_YRS 0;
BA_ "GenSigSendType" SG_ 308 Acceleration_Y 0;
BA_ "GenSigStartValue" SG_ 308 Acceleration_Y 796;
BA_ "GenSigSendType" SG_ 308 Acceleration_X 0;
BA_ "GenSigStartValue" SG_ 308 Acceleration_X 796;
BA_ "GenSigSendType" SG_ 308 YRSSt 0;
BA_ "GenSigSendType" SG_ 308 YawRate 0;
BA_ "GenSigStartValue" SG_ 308 YawRate 2000;
BA_ "GenSigSendType" SG_ 308 Checksum_ESP_3 0;
BA_ "GenSigSendType" SG_ 306 LiveCounter_ESP_2 0;
BA_ "GenSigSendType" SG_ 306 WorkingSt_EPB 0;
BA_ "GenSigSendType" SG_ 306 Checksum_ESP_2 0;
BA_ "GenSigSendType" SG_ 586 DoorSt_FL 0;
BA_ "GenSigSendType" SG_ 586 MirrorFoldSt_FL 0;
BA_ "GenSigSendType" SG_ 560 AutoLightMode 0;
BA_ "GenSigSendType" SG_ 560 HazardWarningSt 0;
BA_ "GenSigSendType" SG_ 560 TurningSt_right 0;
BA_ "GenSigSendType" SG_ 560 TurningSt_Left 0;
BA_ "GenSigSendType" SG_ 560 HighBeamSt_FR 0;
BA_ "GenSigSendType" SG_ 560 HighBeamSt_FL 0;
BA_ "GenSigSendType" SG_ 560 LowBeamSt_FR 0;
BA_ "GenSigSendType" SG_ 560 LowBeamSt_FL 1;
BA_ "GenSigSendType" SG_ 304 LiveCounter_ABS_3 0;
BA_ "GenSigInactiveValue" SG_ 304 WheelPulse_RR 255;
BA_ "GenSigSendType" SG_ 304 WheelPulse_RR 0;
BA_ "GenSigInactiveValue" SG_ 304 WheelPulse_RL 255;
BA_ "GenSigSendType" SG_ 304 WheelPulse_RL 0;
BA_ "GenSigInactiveValue" SG_ 304 WheelPulse_FR 255;
BA_ "GenSigSendType" SG_ 304 WheelPulse_FR 0;
BA_ "GenSigInactiveValue" SG_ 304 WheelPulse_FL 255;
BA_ "GenSigSendType" SG_ 304 WheelPulse_FL 0;
BA_ "GenSigSendType" SG_ 304 Checksum_ABS_3 0;
BA_ "GenSigSendType" SG_ 194 WheelSpeed_RR 0;
BA_ "GenSigInactiveValue" SG_ 194 WheelSpeed_RL 32767;
BA_ "GenSigSendType" SG_ 194 WheelSpeed_RL 0;
BA_ "GenSigSendType" SG_ 194 LiveCounter_ABS_2 0;
BA_ "GenSigSendType" SG_ 194 Checksum_ABS_2 0;
BA_ "GenSigSendType" SG_ 2015 Diag_Fun_Req 0;
BA_ "GenSigSendType" SG_ 1838 AVS_Phy_Resp 0;
BA_ "GenSigSendType" SG_ 1830 AVS_Phy_Req 0;
BA_ "GenSigSendType" SG_ 656 HandParkingBrakeSt 0;
BA_ "GenSigSendType" SG_ 656 OdometerValue 0;
BA_ "GenSigTimeoutTime" SG_ 562 PowerMode 500;
BA_ "GenSigInactiveValue" SG_ 562 PowerMode 15;
BA_ "GenSigSendType" SG_ 562 PowerMode 0;
BA_ "GenSigSendType" SG_ 180 LiveCounter_TCU_3 0;
BA_ "GenSigSendType" SG_ 180 Checksum_TCU_3 0;
BA_ "GenSigTimeoutTime" SG_ 180 LeverInfo 200;
BA_ "GenSigSendType" SG_ 180 LeverInfo 0;
BA_ "GenSigSendType" SG_ 192 LiveCounter_ABS_1 0;
BA_ "GenSigInactiveValue" SG_ 192 DrivingDirection 3;
BA_ "GenSigSendType" SG_ 192 DrivingDirection 0;
BA_ "GenSigSendType" SG_ 192 VehicleSpeed 0;
BA_ "GenSigInactiveValue" SG_ 192 VehicleSpeed 32767;
BA_ "GenSigSendType" SG_ 192 WheelSpeed_FR 0;
BA_ "GenSigSendType" SG_ 192 WheelSpeed_FL 0;
BA_ "GenSigInactiveValue" SG_ 192 WheelSpeed_FL 32767;
BA_ "GenSigSendType" SG_ 192 Checksum_ABS_1 0;
BA_ "GenSigStartValue" SG_ 208 SAS_St 1;
BA_ "GenSigSendType" SG_ 208 SAS_St 0;
BA_ "GenSigSendType" SG_ 208 LiveCounter_SAS_1 0;
BA_ "GenSigSendType" SG_ 208 Checksum_SAS_1 0;
BA_ "GenSigSendType" SG_ 208 SteeringWAngleSign 0;
BA_ "GenSigSendType" SG_ 208 SteeringWAngle 0;
BA_ "GenSigSendType" SG_ 600 AVSTurnLightFollowupFunctionSt 0;
BA_ "GenSigSendType" SG_ 600 AVS_RemoteViewModeFeedback 0;
BA_ "GenSigSendType" SG_ 600 RemoteMonitoringModeSt_AVS 0;
BA_ "GenSigSendType" SG_ 600 RemoteMonitoringSt_AVS 0;
BA_ "GenSigSendType" SG_ 600 RemoteMonitoringSharpnessSt_AVS 0;
BA_ "GenSigSendType" SG_ 600 AVS_RemoteSharpnessFeedback 0;
BA_ "GenSigSendType" SG_ 600 AVS_RemoteMonitoringFeedback 0;
BA_ "GenSigSendType" SG_ 600 AVS_PDWarning_Rear 0;
BA_ "GenSigSendType" SG_ 600 AVS_PDWarning_Front 0;
BA_ "GenSigSendType" SG_ 600 AVS_CalibrationSt 0;
BA_ "GenSigSendType" SG_ 600 AVS_AbnormalTip 0;
BA_ "GenSigSendType" SG_ 600 AVSCameraBlockageSt_Right 0;
BA_ "GenSigSendType" SG_ 600 AVSCameraBlockageSt_Left 0;
BA_ "GenSigSendType" SG_ 600 AVSCameraBlockageSt_Rear 0;
BA_ "GenSigSendType" SG_ 600 AVSCameraBlockageSt_Front 0;
BA_ "GenSigSendType" SG_ 600 FoundSlotBuzzerTip 0;
BA_ "GenSigSendType" SG_ 600 BlindSpotFilledFunctionInd 0;
BA_ "GenSigSendType" SG_ 600 MODWarning_Rear 0;
BA_ "GenSigSendType" SG_ 600 MODWarning_Front 0;
BA_ "GenSigSendType" SG_ 600 MODSt_AVS 0;
BA_ "GenSigSendType" SG_ 600 AVSViewtype 0;
BA_ "GenSigSendType" SG_ 600 AVS_SpeechControlFeedback 0;
BA_ "GenSigSendType" SG_ 600 SwitchScreenRequest_AVS 0;
BA_ "GenSigSendType" SG_ 600 DybanicPGSSt_AVS 1;
BA_ "GenSigSendType" SG_ 600 AVSCameraErrorSt_Right 1;
BA_ "GenSigSendType" SG_ 600 AVSCameraErrorSt_Rear 1;
BA_ "GenSigSendType" SG_ 600 AVSCameraErrorSt_Left 1;
BA_ "GenSigSendType" SG_ 600 LanguageTypeSt_AVS 1;
BA_ "GenSigSendType" SG_ 600 AVSCameraErrorSt_Front 1;
BA_ "GenSigSendType" SG_ 600 AVSSt 1;
BA_ "GenSigSendType" SG_ 600 AVSViewMode 1;
BA_ "GenSigSendType" SG_ 600 AVSErrorSt 1;
VAL_ 3221225472 FogLightSt_FR 1 "On" 0 "Off" ;
VAL_ 3221225472 FogLightSt_FL 1 "On" 0 "Off" ;
VAL_ 3221225472 PDC_SpeechControlFeedback 15 "Reserved" 14 "Reserved" 13 "Reserved" 12 "Reserved" 11 "Reserved" 10 "Reserved" 9 "Reserved" 8 "Reserved" 7 "Reserved" 6 "Reserved" 5 "Reserved" 4 "On Failure" 3 "On Success" 2 "Off Failure" 1 "Off Success" 0 "Inactive" ;
VAL_ 3221225472 MinObjectRange 15 "Invalid Value" 14 "Reserved" 13 "Reserved" 12 "Reserved" 11 "Rear and Front Range 3" 10 "Rear and Front Range 2" 9 "Rear and Front Range 1" 8 "Reserved" 7 "Front Range 3" 6 "Front Range 2" 5 "Front Range 1" 4 "Reserved" 3 "Rear Range 3" 2 "Rear Range 2" 1 "Rear Range 1" 0 "No Object" ;
VAL_ 3221225472 RadarSysSt_Side 1 "On" 0 "Off" ;
VAL_ 605 SensorBlockageSt_FL 1 "Blockage" 0 "No Blockage" ;
VAL_ 605 SensorBlockageSt_FML 1 "Blockage" 0 "No Blockage" ;
VAL_ 605 SensorBlockageSt_FMR 1 "Blockage" 0 "No Blockage" ;
VAL_ 605 SensorBlockageSt_FR 1 "Blockage" 0 "No Blockage" ;
VAL_ 605 SensorBlockageSt_RL 1 "Blockage" 0 "No Blockage" ;
VAL_ 605 SensorBlockageSt_RML 1 "Blockage" 0 "No Blockage" ;
VAL_ 605 SensorBlockageSt_RMR 1 "Blockage" 0 "No Blockage" ;
VAL_ 605 SensorBlockageSt_RR 1 "Blockage" 0 "No Blockage" ;
VAL_ 616 WarningCmd_RCTA_Right 3 "Reserved" 2 "Warning level 2" 1 "Warning level 1" 0 "Inactive" ;
VAL_ 616 WarningCmd_RCTA_left 3 "Reserved" 2 "Warning level 2" 1 "Warning level 1" 0 "Inactive" ;
VAL_ 672 RemoteAVSViewModeReq 15 "Reserved" 14 "Reserved" 13 "Reserved" 12 "Reserved" 11 "Screen Dragged 3D View" 10 "Rear Rim View" 9 "Front Rim view" 8 "Reserved" 7 "Rear Wide View" 6 "Frnot Wide View" 5 "Top View and Right View" 4 "Top View and Left View" 3 "Top View and Rear View" 2 "Top View and Front View" 1 "All Top View" 0 "inactiive" ;
VAL_ 672 RemoteAVSSharpnessReq 3 "Reserved" 2 "HD" 1 "SD" 0 "Inactive" ;
VAL_ 672 RemoteMonitoringReq 3 "Reserved" 2 "On" 1 "Off" 0 "Inactive" ;
VAL_ 591 DoorSt_RR 1 "Open" 0 "Close" ;
VAL_ 590 DoorSt_RL 1 "Open" 0 "Close" ;
VAL_ 420 MCP_AVSandFRadarSwitch 1 "Pressed" 0 "Not pressed" ;
VAL_ 650 TargetSelection_ConfirmReq 1 "Active" 0 "Inactive" ;
VAL_ 650 TargetSelection_ParkDirection 3 "Reserved" 2 "Left" 1 "Right" 0 "Inactive" ;
VAL_ 650 TargetSelection_ParkType 7 "Reserved" 6 "Reserved" 5 "Reserved" 4 "Auto" 3 "Backward Oblique" 2 "Backward Perpendicular" 1 "Parallel" 0 "Inactive
" ;
VAL_ 650 TargetSelection_Area 1 "Green Area" 0 "Red Area
" ;
VAL_ 897 ScreenPressType2 3 "Pen move" 2 " Pen up" 1 "Pen down" 0 "Not touch" ;
VAL_ 897 ScreenPressType1 3 "Pen move" 2 " Pen up" 1 "Pen down" 0 "Not touch" ;
VAL_ 643 HU_BlindSpotFilledFunctionReq 3 "Reserved" 2 "On" 1 "Off" 0 "Inactive" ;
VAL_ 657 DisplayTheme 7 "Reserved" 6 "Reserved" 5 "Reserved" 4 "Reserved" 3 "Theme 3" 2 "Theme 2" 1 "Theme 1" 0 "Not define" ;
VAL_ 688 GW_OTAMode 7 "Reserved" 6 "Reserved" 5 "Reserved" 4 "Reserved" 3 "Reserved" 2 "Reserved" 1 "OTA Mode" 0 "Normal Mode" ;
VAL_ 688 GW_RemoteVehicleMode 1 "Remote Mode" 0 "Normal Mode" ;
VAL_ 534 DMS_VehicleModeInfo 15 "Invalid value" 14 " Reserved" 13 " Reserved" 12 " Reserved" 11 " Reserved" 10 " Reserved" 9 " Reserved" 8 " Reserved" 7 " Reserved" 6 " Reserved" 5 " Reserved" 4 "Snow" 3 "Sport" 2 "Comfort" 1 "Eco" 0 "Auto" ;
VAL_ 564 EngineHoodSt 1 "Open" 0 "Close" ;
VAL_ 604 SwitchScreenRequest_PDC 3 "Reserved" 2 "PDC Display Exit Request" 1 "PDC Display Enter Request" 0 "Inactive" ;
VAL_ 604 PDCAutoOnFunctionInd 1 "ON" 0 "Off
" ;
VAL_ 604 RadarSysSt_RearSide 1 "On" 0 "Off" ;
VAL_ 604 RadarSysSt_FrontSide 1 "On" 0 "Off" ;
VAL_ 604 SensorErrorSt_FL 1 "ERROR" 0 "No ERROR" ;
VAL_ 604 ObjectRange_FL 7 "Invalid Value" 6 "Range 6" 5 "Range 5" 4 "Range 4" 3 "Range 3" 2 "Range 2" 1 "Range 1" 0 "No Object" ;
VAL_ 604 SensorErrorSt_FML 1 "ERROR" 0 "No ERROR" ;
VAL_ 604 ObjectRange_FML 7 "Invalid Value" 6 "Range 6" 5 "Range 5" 4 "Range 4" 3 "Range 3" 2 "Range 2" 1 "Range 1" 0 "No Object" ;
VAL_ 604 SensorErrorSt_FMR 1 "ERROR" 0 "No ERROR" ;
VAL_ 604 ObjectRange_FMR 7 "Invalid Value" 6 "Range 6" 5 "Range 5" 4 "Range 4" 3 "Range 3" 2 "Range 2" 1 "Range 1" 0 "No Object" ;
VAL_ 604 SensorErrorSt_FR 1 "ERROR" 0 "No ERROR" ;
VAL_ 604 ObjectRange_FR 7 "Invalid Value" 6 "Range 6" 5 "Range 5" 4 "Range 4" 3 "Range 3" 2 "Range 2" 1 "Range 1" 0 "No Object" ;
VAL_ 604 SensorErrorSt_RL 1 "ERROR" 0 "No ERROR" ;
VAL_ 604 ObjectRange_RL 7 "Invalid Value" 6 "Range 6" 5 "Range 5" 4 "Range 4" 3 "Range 3" 2 "Range 2" 1 "Range 1" 0 "No Object" ;
VAL_ 604 SensorErrorSt_RML 1 "ERROR" 0 "No ERROR" ;
VAL_ 604 ObjectRange_RML 7 "Invalid Value" 6 "Range 6" 5 "Range 5" 4 "Range 4" 3 "Range 3" 2 "Range 2" 1 "Range 1" 0 "No Object" ;
VAL_ 604 SensorErrorSt_RMR 1 "ERROR" 0 "No ERROR" ;
VAL_ 604 BuzeerCmd_PDC 7 "Reserved" 6 "System fault tone" 5 "Normal start tone" 4 "Low frequency tone" 3 "Reserved" 2 "High frequency tone" 1 "Continuous tone" 0 "Inactive" ;
VAL_ 604 ObjectRange_RMR 7 "Invalid Value" 6 "Range 6" 5 "Range 5" 4 "Range 4" 3 "Range 3" 2 "Range 2" 1 "Range 1" 0 "No Object" ;
VAL_ 604 SensorErrorSt_RR 1 "ERROR" 0 "No ERROR" ;
VAL_ 604 ObjectRange_RR 7 "Invalid Value" 6 "Range 6" 5 "Range 5" 4 "Range 4" 3 "Range 3" 2 "Range 2" 1 "Range 1" 0 "No Object" ;
VAL_ 604 RadarSysSt_Rear 1 "On" 0 "Off" ;
VAL_ 604 RadarSysSt_Front 1 "On" 0 "Off" ;
VAL_ 604 ErrorSt_PDC 1 "ERROR" 0 "No ERROR" ;
VAL_ 604 SysSt_PDC 1 "On" 0 "Off" ;
VAL_ 588 MirrorFoldSt_FR 3 "Reserved" 2 "Reserved" 1 "Fold" 0 "Unfold" ;
VAL_ 588 DoorSt_FR 1 "Open" 0 "Close" ;
VAL_ 578 LuggageDoorSt 1 "Open" 0 "Close" ;
VAL_ 148 BakePedalSt 3 "Error" 2 "Reserved" 1 "Actuated" 0 "Not Actuated" ;
VAL_ 652 HU_SpeedReq_AVS 3 "Reserved" 2 "on" 1 "off" 0 "inactive" ;
VAL_ 648 AVSTurnLightFollowupFunctionReq 3 "Reserve" 2 "On" 1 "Off" 0 "Inactive
" ;
VAL_ 648 HU_RemoteMonitoringSt 1 "ON" 0 "Off
" ;
VAL_ 648 HU_AVM_RemoteMonitoringIFrameReq 1 "Active" 0 "Inactive" ;
VAL_ 648 HU_AVM_RemoteMonitorSharpnessSet 3 "Reserved" 2 "HD" 1 "SD" 0 "Inactive" ;
VAL_ 648 AVSViewtypeReq 15 "reserved" 14 "Calibration Mode" 13 "Factory Mode" 12 "Reserved" 11 "Screen Dragged 3D View" 10 "Rear Rim View" 9 "Front Rim view" 8 "Reserved" 7 "Rear Wide View" 6 "Frnot Wide View" 5 "Top View and Right View" 4 "Top View and Left View" 3 "Top View and Rear View" 2 "Top View and Front View" 1 "All Top View" 0 "inactiive" ;
VAL_ 648 AVSMonitoringVideoModeReq 1 "Active" 0 "Inactive" ;
VAL_ 648 AVSFunctionReq 3 "Reserved" 2 "On" 1 "Off" 0 "Inactive" ;
VAL_ 648 SwitchScreenResponseAVS 3 "Reserved" 2 "AVS Exitr Response" 1 "AVS Enter Response" 0 "Inactive" ;
VAL_ 648 LanguageSet 15 "reserved" 14 "reserved" 13 "reserved" 12 "reserved" 11 "reserved" 10 "reserved" 9 "reserved" 8 "reserved" 7 "reserved" 6 "Russian" 5 "Arabic" 4 "French" 3 "English" 2 "Traditional Chinese" 1 "Simplified Chinese" 0 "Inactive" ;
VAL_ 648 MODReq 3 "Reserved" 2 "on" 1 "off" 0 "inactive" ;
VAL_ 648 DynamicPGSReq 3 "Reserved" 2 "on" 1 "off" 0 "inactive" ;
VAL_ 648 AVSFunctionExitReq 1 "active" 0 "Inactive" ;
VAL_ 648 AVSViewModeReq 15 "invaild value" 14 "Calibration Mode" 13 "Factory Mode" 12 "Reserved" 11 "Screen Dragged 3D View" 10 "Rear Rim View" 9 "Front Rim view" 8 "Reserved" 7 "Rear Wide View" 6 "Frnot Wide View" 5 "Top View and Right View" 4 "Top View and Left View" 3 "Top View and Rear View" 2 "Top View and Front View" 1 "All Top View" 0 "inactiive" ;
VAL_ 308 ErrorSt_YRS 1 "Error" 0 "No Error" ;
VAL_ 308 YRSSt 1 "Not Calibrated" 0 "Calibrated" ;
VAL_ 306 WorkingSt_EPB 3 "unkown" 2 "Locked" 1 "Releasing/Locking" 0 "Released" ;
VAL_ 586 DoorSt_FL 1 "Open" 0 "Close" ;
VAL_ 586 MirrorFoldSt_FL 3 "Reserved" 2 "Reserved" 1 "Fold" 0 "Unfold" ;
VAL_ 560 AutoLightMode 1 "Active" 0 "Inactive" ;
VAL_ 560 HazardWarningSt 1 "active" 0 "Inactive" ;
VAL_ 560 TurningSt_right 1 "active" 0 "Inactive" ;
VAL_ 560 TurningSt_Left 1 "active" 0 "Inactive" ;
VAL_ 560 HighBeamSt_FR 1 "On" 0 "Off" ;
VAL_ 560 HighBeamSt_FL 1 "On" 0 "Off" ;
VAL_ 560 LowBeamSt_FR 1 "On" 0 "Off" ;
VAL_ 560 LowBeamSt_FL 1 "On" 0 "Off" ;
VAL_ 656 HandParkingBrakeSt 3 "Error" 2 "Reserved" 1 "Brake Tiqhtened" 0 "Brake Released" ;
VAL_ 562 PowerMode 7 "InvaildValue" 6 "Reserved" 5 "Reserved" 4 "IgnitionOn" 3 "Reserved" 2 "Reserved" 1 "Reserved" 0 "OFF" ;
VAL_ 180 LeverInfo 14 "No Connection" 13 "Reserved" 12 "Reserved" 11 "Reserved" 10 "Reserved" 9 "Reserved" 15 "Error Value" 8 "Reserved" 7 "Resrved
" 6 "6: E

" 5 "5: M

" 4 "4: S

" 3 "3: D

" 2 "2: N

" 1 "1: R

" 0 "0: P

" ;
VAL_ 192 DrivingDirection 3 "invaild Value" 2 "Backward" 1 "Forward" 0 "Stop" ;
VAL_ 208 SAS_St 3 "Pemanent erroe Del" 2 "Intemittent erroe Del" 1 "SAS not Cailbrated" 0 "SASAng and SpeCorrect" ;
VAL_ 208 SteeringWAngleSign 1 "1: Right" 0 "0: Left

" ;
VAL_ 600 AVSTurnLightFollowupFunctionSt 1 "ON" 0 "Off
" ;
VAL_ 600 AVS_RemoteViewModeFeedback 31 "Reserved" 30 "Reserved" 29 "Reserved" 28 "Reserved" 27 "Reserved" 26 "Reserved" 25 "Reserved" 24 "Rear Rim view Failure" 23 "Rear Rim view Success" 22 "Front Rim view Failure" 21 "Front Rim view Success" 20 " Reserved" 19 " Reserved" 18 "Rear Wide View Failure" 17 "Rear Wide View Success" 16 " Front Wide View Failure" 15 "Front Wide View Success" 14 " Top View and Right View Failure" 13 "Top View and Right View Success" 12 "Top View and Left View Failure" 11 "Top View and Left View Success" 10 "Top View and Rear View Failure" 9 "Top View and Rear View Success" 8 " Top View and Front View Failure" 7 "Top View and Front View Success" 6 "All Top View Failure" 5 "All Top View Success" 4 "On Failure" 3 "On Success" 2 "Off Failure" 1 "Off Success" 0 "Inactive" ;
VAL_ 600 RemoteMonitoringModeSt_AVS 1 "Video Mode" 0 "Picture Mode
" ;
VAL_ 600 RemoteMonitoringSt_AVS 1 "ON" 0 "Off
" ;
VAL_ 600 RemoteMonitoringSharpnessSt_AVS 1 "HD" 0 "SD
" ;
VAL_ 600 AVS_RemoteSharpnessFeedback 7 "Reserved" 6 "Reserved" 5 "Reserved" 4 "HD Failure" 3 "HD Success" 2 "SD Failure" 1 "SD Success" 0 "Inactive" ;
VAL_ 600 AVS_RemoteMonitoringFeedback 7 "Reserved" 6 "Reserved" 5 "Reserved" 4 "On Failure" 3 "On Success" 2 "Off Failure" 1 " Off Success" 0 "Inactive" ;
VAL_ 600 AVS_PDWarning_Rear 1 "Waring" 0 "No warning" ;
VAL_ 600 AVS_PDWarning_Front 1 "Waring" 0 "No warning" ;
VAL_ 600 AVS_CalibrationSt 3 "Reserved" 2 "Calibrated" 1 "Calibrating" 0 "Not calibrated" ;
VAL_ 600 AVS_AbnormalTip 7 "Reserved" 6 "Reserved" 5 "Reserved" 4 "Reserved" 3 "Reserved" 2 "Reserved" 1 "Speed too high" 0 "Inactive" ;
VAL_ 600 AVSCameraBlockageSt_Right 1 "Blockage" 0 "No Blockage" ;
VAL_ 600 AVSCameraBlockageSt_Left 1 "Blockage" 0 "No Blockage" ;
VAL_ 600 AVSCameraBlockageSt_Rear 1 "Blockage" 0 "No Blockage" ;
VAL_ 600 AVSCameraBlockageSt_Front 1 "Blockage" 0 "No Blockage" ;
VAL_ 600 FoundSlotBuzzerTip 1 "Active" 0 "Inactive" ;
VAL_ 600 BlindSpotFilledFunctionInd 1 "ON" 0 "Off
" ;
VAL_ 600 MODWarning_Rear 1 "Waring" 0 "No warning" ;
VAL_ 600 MODWarning_Front 1 "Waring" 0 "No warning" ;
VAL_ 600 MODSt_AVS 1 "ON" 0 "Off
" ;
VAL_ 600 AVSViewtype 3 "Reserved" 2 "Other" 1 "3D" 0 "2D" ;
VAL_ 600 SwitchScreenRequest_AVS 3 "Reserved" 2 "AVS Exit Request" 1 "AVS Enter Request" 0 "Inactive" ;
VAL_ 600 DybanicPGSSt_AVS 1 "1: Error" 0 "0: No Error

" ;
VAL_ 600 AVSCameraErrorSt_Right 1 "1: Error" 0 "0: No Error

" ;
VAL_ 600 AVSCameraErrorSt_Rear 1 "1: Error" 0 "0: No Error

" ;
VAL_ 600 AVSCameraErrorSt_Left 1 "1: Error" 0 "0: No Error

" ;
VAL_ 600 LanguageTypeSt_AVS 15 "reserved" 14 "reserved" 13 "reserved" 12 "reserved" 11 "reserved" 10 "reserved" 9 "reserved" 8 "reserved" 7 "reserved" 6 "reserved" 5 "Russian" 4 "Arabic" 3 "French" 2 "English" 1 "Traditional Chinese" 0 "Simple Chinese" ;
VAL_ 600 AVSCameraErrorSt_Front 1 "1: Error" 0 "0: No Error

" ;
VAL_ 600 AVSSt 1 "Function" 0 "off" ;
VAL_ 600 AVSViewMode 15 "invaild value" 14 "Calibration Mode" 13 "Factory Mode" 12 "Reserved" 11 "Screen Dragged 3D View" 10 "Rear Rim View" 9 "Front Rim view" 8 "Reserved" 7 "Rear Wide View" 6 "Frnot Wide View" 5 "Top View and Right View" 4 "Top View and Left View" 3 "Top View and Rear View" 2 "Top View and Front View" 1 "All Top View" 0 "inactiive" ;
VAL_ 600 AVSErrorSt 1 "1: Error" 0 "0: No Error

" ;
